# AT91SAM9M11 register map
Vendor: Atmel; Series: SAM9M; File version: 20130207
Registers are 32-bit, read-write, reset 0x0 unless marked. A register's access mark holds for its fields unless they carry their own. Offsets are from the block's base; [hi:lo] are bit positions; {n}, {i} and the like mark numbered series.

## PIOA — Parallel Input/Output Controller A
Base 0xFFFFF200; register names take the prefix PIOA_
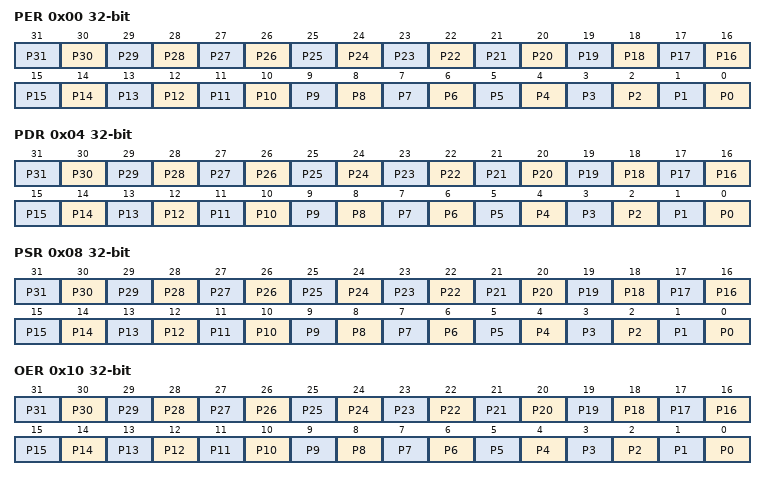
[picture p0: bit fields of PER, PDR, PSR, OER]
0x00 PER wo reset not defined — PIO Enable Register
  [n] P{n} (n=0..31) — PIO Enable
0x04 PDR wo reset not defined — PIO Disable Register
  [n] P{n} (n=0..31) — PIO Disable
0x08 PSR ro reset not defined — PIO Status Register
  [n] P{n} (n=0..31) — PIO Status
0x10 OER wo reset not defined — Output Enable Register
  [n] P{n} (n=0..31) — Output Enable
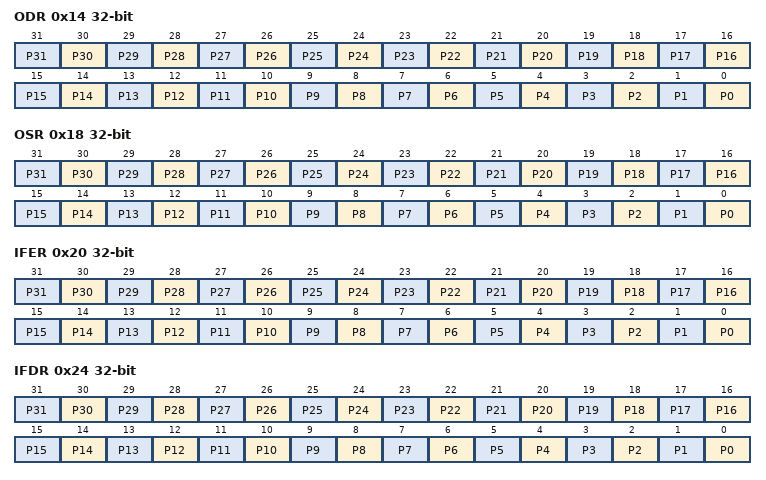
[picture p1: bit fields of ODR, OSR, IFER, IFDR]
0x14 ODR wo reset not defined — Output Disable Register
  [n] P{n} (n=0..31) — Output Disable
0x18 OSR ro — Output Status Register
  [n] P{n} (n=0..31) — Output Status
0x20 IFER wo reset not defined — Glitch Input Filter Enable Register
  [n] P{n} (n=0..31) — Input Filter Enable
0x24 IFDR wo reset not defined — Glitch Input Filter Disable Register
  [n] P{n} (n=0..31) — Input Filter Disable
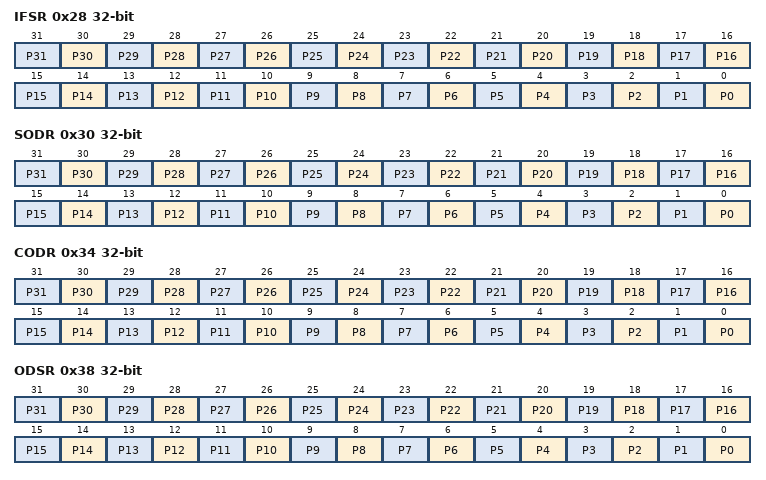
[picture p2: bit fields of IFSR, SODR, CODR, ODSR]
0x28 IFSR ro — Glitch Input Filter Status Register
  [n] P{n} (n=0..31) — Input Filer Status
0x30 SODR wo reset not defined — Set Output Data Register
  [n] P{n} (n=0..31) — Set Output Data
0x34 CODR wo reset not defined — Clear Output Data Register
  [n] P{n} (n=0..31) — Clear Output Data
0x38 ODSR reset not defined — Output Data Status Register
  [n] P{n} (n=0..31) — Output Data Status
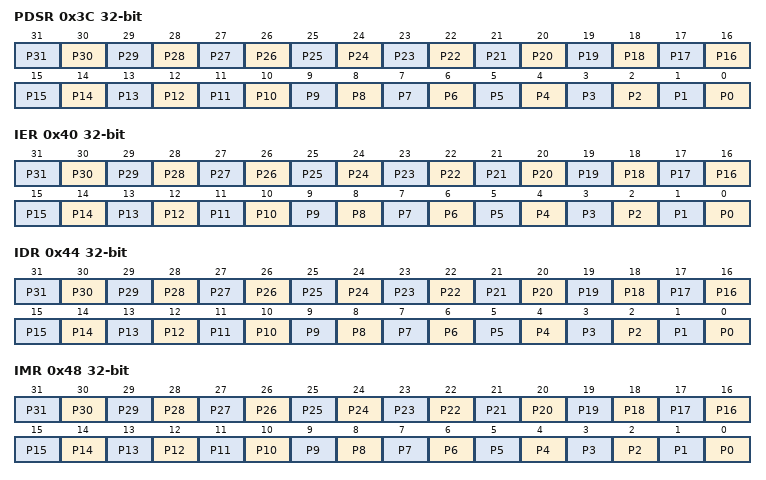
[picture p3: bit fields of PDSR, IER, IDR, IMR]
0x3C PDSR ro reset not defined — Pin Data Status Register
  [n] P{n} (n=0..31) — Output Data Status
0x40 IER wo reset not defined — Interrupt Enable Register
  [n] P{n} (n=0..31) — Input Change Interrupt Enable
0x44 IDR wo reset not defined — Interrupt Disable Register
  [n] P{n} (n=0..31) — Input Change Interrupt Disable
0x48 IMR ro — Interrupt Mask Register
  [n] P{n} (n=0..31) — Input Change Interrupt Mask
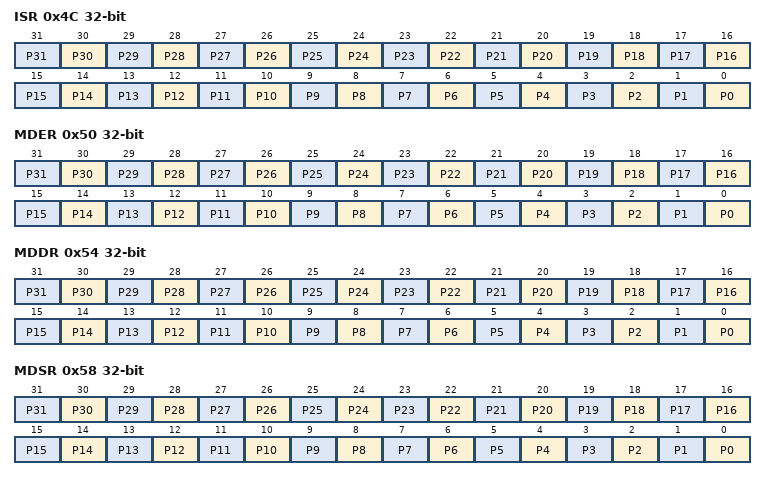
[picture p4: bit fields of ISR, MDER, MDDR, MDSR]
0x4C ISR ro — Interrupt Status Register
  [n] P{n} (n=0..31) — Input Change Interrupt Status
0x50 MDER wo reset not defined — Multi-driver Enable Register
  [n] P{n} (n=0..31) — Multi Drive Enable.
0x54 MDDR wo reset not defined — Multi-driver Disable Register
  [n] P{n} (n=0..31) — Multi Drive Disable.
0x58 MDSR ro — Multi-driver Status Register
  [n] P{n} (n=0..31) — Multi Drive Status.
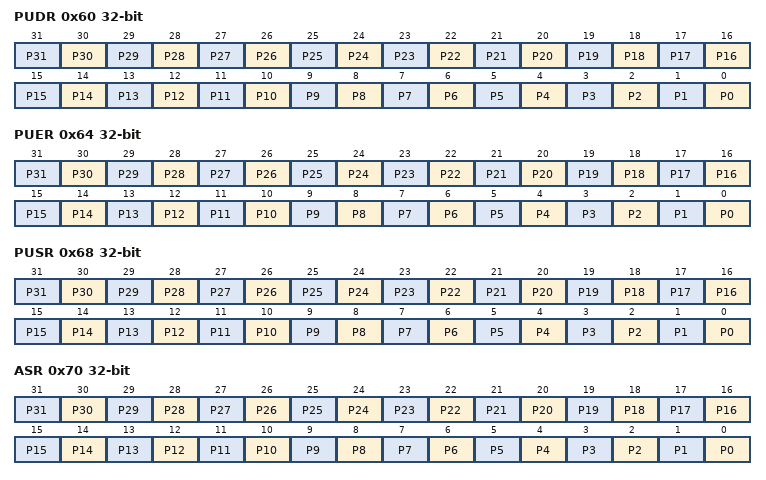
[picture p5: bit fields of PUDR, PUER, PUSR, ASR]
0x60 PUDR wo reset not defined — Pull-up Disable Register
  [n] P{n} (n=0..31) — Pull Up Disable.
0x64 PUER wo reset not defined — Pull-up Enable Register
  [n] P{n} (n=0..31) — Pull Up Enable.
0x68 PUSR ro — Pad Pull-up Status Register
  [n] P{n} (n=0..31) — Pull Up Status.
0x70 ASR wo reset not defined — Peripheral A Select Register
  [n] P{n} (n=0..31) — Peripheral A Select.
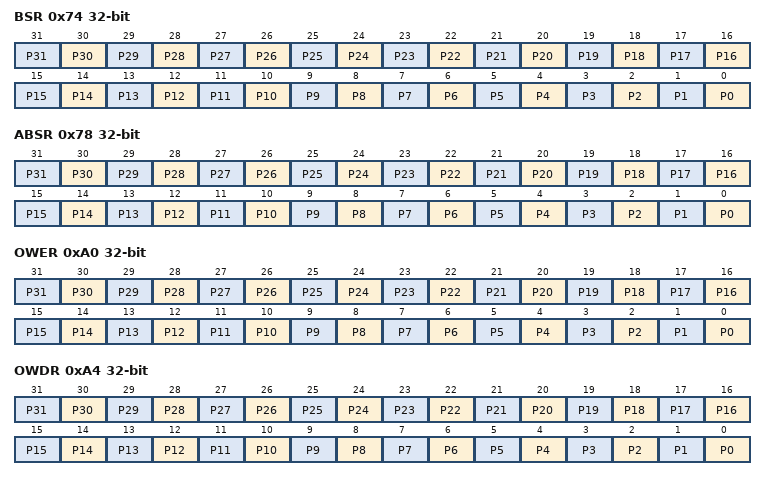
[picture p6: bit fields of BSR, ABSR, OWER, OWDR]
0x74 BSR wo reset not defined — Peripheral B Select Register
  [n] P{n} (n=0..31) — Peripheral B Select.
0x78 ABSR ro — AB Status Register
  [n] P{n} (n=0..31) — Peripheral A B Status.
0xA0 OWER wo reset not defined — Output Write Enable
  [n] P{n} (n=0..31) — Output Write Enable.
0xA4 OWDR wo reset not defined — Output Write Disable
  [n] P{n} (n=0..31) — Output Write Disable.
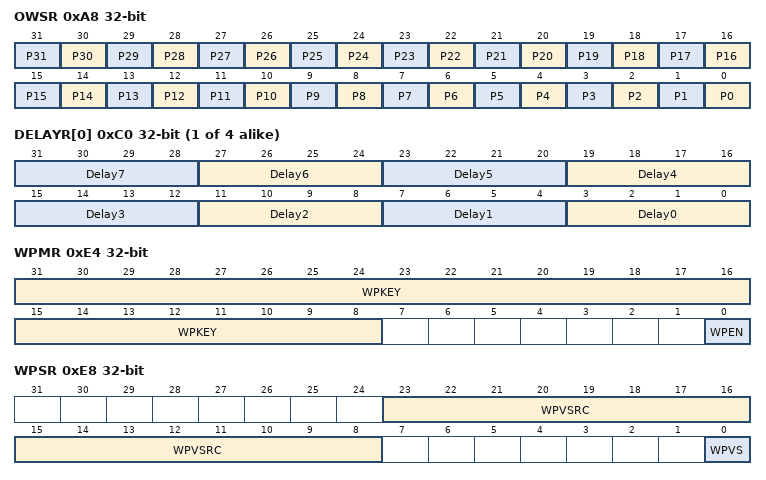
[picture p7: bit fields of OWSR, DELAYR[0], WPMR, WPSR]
0xA8 OWSR ro — Output Write Status Register
  [n] P{n} (n=0..31) — Output Write Status.
{0xC0+4i} DELAYR[{i}] (i=0..3) reset not defined — I/O Delay Register
  [4n+3:4n] Delay{n} (n=0..7)
0xE4 WPMR — Write Protect Mode Register
  [31:8] WPKEY — Write Protect KEY
  [0] WPEN — Write Protect Enable
0xE8 WPSR ro — Write Protect Status Register
  [23:8] WPVSRC — Write Protect Violation Source
  [0] WPVS — Write Protect Enable

## PIOB — Parallel Input/Output Controller B
Base 0xFFFFF400; register names take the prefix PIOB_
Registers as PIOA.

## PIOC — Parallel Input/Output Controller C
Base 0xFFFFF600; register names take the prefix PIOC_
Registers as PIOA.

## PIOD — Parallel Input/Output Controller D
Base 0xFFFFF800; register names take the prefix PIOD_
Registers as PIOA.

## PIOE — Parallel Input/Output Controller E
Base 0xFFFFFA00; register names take the prefix PIOE_
Registers as PIOA.
